AUTOSAR XML (schema 00048)
package /ComponentTypes
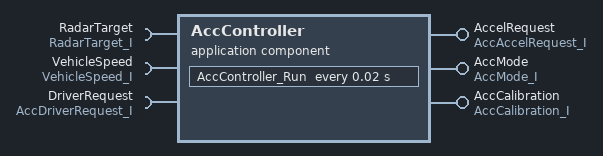
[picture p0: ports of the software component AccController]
  application sw component type AccController
    require port RadarTarget: required-interface=RadarTarget_I
      required-com-specs:
        data-element=TargetDistance, alive-timeout=0.12, handle-never-received=true, init-value=constant-reference=TargetDistance_IV
        data-element=TargetRelativeSpeed, alive-timeout=0.12, handle-never-received=true, init-value=constant-reference=RelativeSpeed_IV
        data-element=TargetValid, alive-timeout=0.12, handle-never-received=true, init-value=constant-reference=RadarTargetValid_IV
    require port VehicleSpeed: nonqueued-receiver-com-spec{data-element=VehicleSpeed, init-value=constant-reference=VehicleSpeed_IV}, required-interface=VehicleSpeed_I
    require port DriverRequest: required-interface=AccDriverRequest_I
      required-com-specs:
        data-element=SetSpeed, init-value=constant-reference=SetSpeed_IV
        data-element=TimeGap, init-value=constant-reference=TimeGap_IV
    provide port AccelRequest: nonqueued-sender-com-spec{data-element=AccelRequest, init-value=constant-reference=LongitudinalAccel_IV}, provided-interface=AccAccelRequest_I
    provide port AccMode: mode-switch-sender-com-spec{enhanced-mode-api=false, mode-group=accMode, queue-length=1}, provided-interface=AccMode_I
    provide port AccCalibration: provided-com-specs=[{operation=ReadParameter, queue-length=1}, {operation=WriteParameter, queue-length=1}], provided-interface=AccCalibration_I
    behavior AccController_InternalBehavior: data-type-mapping=AccTypeMappingSet
      init event IT_AccController_Init: start-on-event=AccController_Init
      timing event TMT_AccController_Run: start-on-event=AccController_Run, period=0.02
      data received event DRT_AccController_OnTargetUpdate_RadarTarget_TargetDistance: start-on-event=AccController_OnTargetUpdate, data=RadarTarget.TargetDistance
      operation invoked event OIT_AccController_ReadParameter_AccCalibration_ReadParameter: start-on-event=AccController_ReadParameter, operation=AccCalibration.ReadParameter
      operation invoked event OIT_AccController_WriteParameter_AccCalibration_WriteParameter: start-on-event=AccController_WriteParameter, operation=AccCalibration.WriteParameter
      port-api-options:
        enable-take-address=false, indirect-api=false, port=AccCalibration
        enable-take-address=false, indirect-api=false, port=AccelRequest
        enable-take-address=false, indirect-api=false, port=AccMode
        enable-take-address=false, indirect-api=false, port=DriverRequest
        enable-take-address=false, indirect-api=false, port=RadarTarget
        enable-take-address=false, indirect-api=false, port=VehicleSpeed
      5 x runnable:
        AccController_Init
        AccController_Run
          data-receive-point-by-arguments:
            6 x access:
              REC_RadarTarget_TargetDistance: accessed-variable=RadarTarget.TargetDistance
              REC_RadarTarget_TargetRelativeSpeed: accessed-variable=RadarTarget.TargetRelativeSpeed
              REC_RadarTarget_TargetValid: accessed-variable=RadarTarget.TargetValid
              REC_VehicleSpeed_VehicleSpeed: accessed-variable=VehicleSpeed.VehicleSpeed
              REC_DriverRequest_SetSpeed: accessed-variable=DriverRequest.SetSpeed
              REC_DriverRequest_TimeGap: accessed-variable=DriverRequest.TimeGap
          data-send-points:
            access SEND_AccelRequest_AccelRequest: accessed-variable=AccelRequest.AccelRequest
        AccController_OnTargetUpdate
          data-receive-point-by-arguments:
            access REC_RadarTarget_TargetDistance: accessed-variable=RadarTarget.TargetDistance
            access REC_RadarTarget_TargetValid: accessed-variable=RadarTarget.TargetValid
        AccController_ReadParameter
        AccController_WriteParameter
  swc implementation AccController_Implementation: behavior=AccController_InternalBehavior
